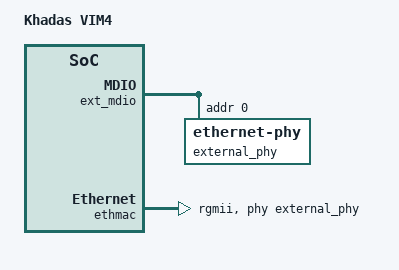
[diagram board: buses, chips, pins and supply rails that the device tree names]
#include "t7_a311d2_an400_drm_hdmitx_only.dts"
#include "coreelec_t7_common.dtsi"

/ {
	model = "Khadas VIM4";
	coreelec-dt-id = "t7_a311d2_khadas_vim4";

	memory@00000000 {
		device_type = "memory";
		linux,usable-memory = <0x00000000 0x00000000 0x00000000 0xE0000000
		                       0x00000001 0x00000000 0x00000001 0x20000000>;
	};

	gpioleds {
		sys_led {
			label = "sys_led";
			gpios = <&gpio GPIOD_6 GPIO_ACTIVE_HIGH>;
			linux,default-trigger = "default-on";
		};
	};

	gpio_keypad {
		key-gpios = <&gpio GPIOD_4 GPIO_ACTIVE_HIGH>;
	};
};

&ext_mdio {
	external_phy: ethernet-phy@0 {
		reg = <0>;
		max-speed = <1000>;
	};
};

&ethmac {
	pinctrl-0 = <&eth_pins>, <&eth_rgmii_pins>;
	pinctrl-names = "default";
	status = "okay";
	phy-mode = "rgmii";
	phy-handle = <&external_phy>;
	mc_val = <0x1621>;
	cali_val = <0xa0000>;
	amlogic,tx-delay-ns = <2>;
};
